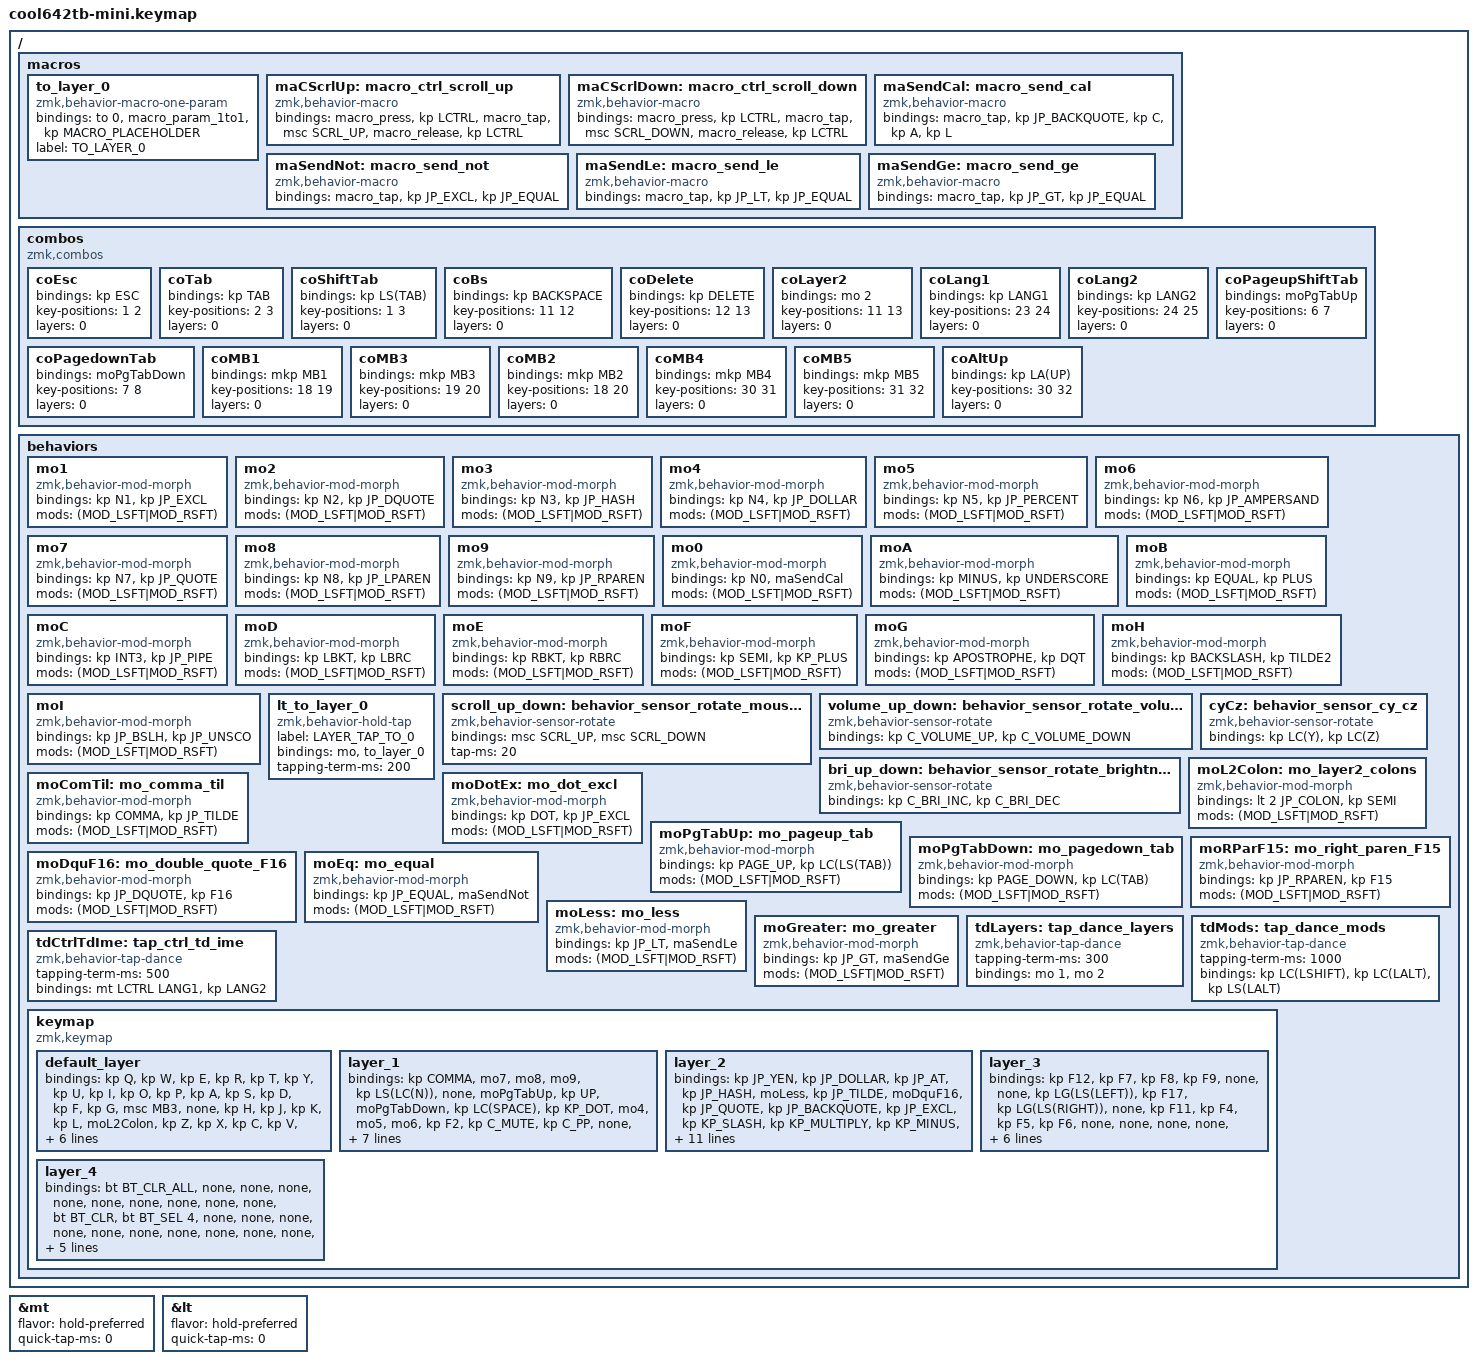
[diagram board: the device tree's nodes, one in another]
#include <behaviors.dtsi>
#include <dt-bindings/zmk/bt.h>
#include <dt-bindings/zmk/keys.h>
#include <dt-bindings/zmk/pointing.h>

#define MOUSE 4
#define SCROLL 5
#define NUM 6
#define ZMK_POINTING_DEFAULT_SCRL_VAL 80
#define JP_DQUOTE       AT                // "
#define JP_AMPERSAND    CARET             // &
#define JP_QUOTE        AMPERSAND         // '
#define JP_EQUAL        UNDER             // =
#define JP_CARET        EQUAL             // ^
#define JP_YEN          0x89              // ¥
#define JP_PLUS         COLON             // +
#define JP_TILDE        PLUS              // ~
#define JP_PIPE         LS(0x89)          // |
#define JP_AT           LEFT_BRACKET      // @
#define JP_COLON        SINGLE_QUOTE      // :
#define JP_ASTERISK     DOUBLE_QUOTES     // *
#define JP_BACKQUOTE    LEFT_BRACE        // `
#define JP_UNSCO   LS(0x87)          // _
#define JP_LBRACKET     RIGHT_BRACKET     // [
#define JP_RBRACKET     BACKSLASH         // ]
#define JP_LPAREN       ASTERISK          // (
#define JP_RPAREN       LEFT_PARENTHESIS  // )
#define JP_LBRACE       RIGHT_BRACE       // {
#define JP_RBRACE       PIPE              // }
#define JP_KANA         LANGUAGE_1        // かな
#define JP_EISU         LANGUAGE_2        // 英数
#define JP_HANZEN       GRAVE             // 半角/全角
#define JP_BSLH         INT1              // (backslash)

// new define

#define JP_EXCL  LS(N1)            // !
#define JP_QUESTION     LS(SLASH)         // ?
#define JP_HASH         LS(N3)            // #
#define JP_DOLLAR       LS(N4)            // $
#define JP_PERCENT      LS(N5)            // %
#define JP_LT           LS(COMMA)         // <
#define JP_GT           LS(DOT)           // >

&mt {
    flavor = "hold-preferred";
    quick-tap-ms = <0>;
};

&lt {
    flavor = "hold-preferred";
    quick-tap-ms = <0>;
};

/ {
    macros {
        to_layer_0: to_layer_0 {
            compatible = "zmk,behavior-macro-one-param";
            #binding-cells = <1>;
            bindings = <&to 0 &macro_param_1to1 &kp MACRO_PLACEHOLDER>;
            label = "TO_LAYER_0";
        };

        maCScrlUp: macro_ctrl_scroll_up {
            compatible = "zmk,behavior-macro";
            #binding-cells = <0>;
            bindings =
                <&macro_press>,
                <&kp LCTRL>,
                <&macro_tap>,
                <&msc SCRL_UP>,
                <&macro_release>,
                <&kp LCTRL>;
        };

        maCScrlDown: macro_ctrl_scroll_down {
            compatible = "zmk,behavior-macro";
            #binding-cells = <0>;
            bindings =
                <&macro_press>,
                <&kp LCTRL>,
                <&macro_tap>,
                <&msc SCRL_DOWN>,
                <&macro_release>,
                <&kp LCTRL>;
        };

        maSendCal: macro_send_cal {
            compatible = "zmk,behavior-macro";
            #binding-cells = <0>;
            bindings = <&macro_tap>, <&kp JP_BACKQUOTE &kp C &kp A &kp L>;
        };

        maSendNot: macro_send_not {
            compatible = "zmk,behavior-macro";
            #binding-cells = <0>;
            bindings = <&macro_tap>, <&kp JP_EXCL &kp JP_EQUAL>;
        };

        maSendLe: macro_send_le {
            compatible = "zmk,behavior-macro";
            #binding-cells = <0>;
            bindings = <&macro_tap>, <&kp JP_LT &kp JP_EQUAL>;
        };

        maSendGe: macro_send_ge {
            compatible = "zmk,behavior-macro";
            #binding-cells = <0>;
            bindings = <&macro_tap>, <&kp JP_GT &kp JP_EQUAL>;
        };
    };

    combos {
        compatible = "zmk,combos";

        // combos layer0
        //Left row1

        coEsc {
            bindings = <&kp ESC>;
            key-positions = <1 2>;
            layers = <0>;
        };

        coTab {
            bindings = <&kp TAB>;
            key-positions = <2 3>;
            layers = <0>;
        };

        coShiftTab {
            bindings = <&kp LS(TAB)>;
            key-positions = <1 3>;
            layers = <0>;
        };

        //Left row2

        coBs {
            bindings = <&kp BACKSPACE>;
            key-positions = <11 12>;
            layers = <0>;
        };

        coDelete {
            bindings = <&kp DELETE>;
            key-positions = <12 13>;
            layers = <0>;
        };

        coLayer2 {
            bindings = <&mo 2>;
            key-positions = <11 13>;
            layers = <0>;
        };

        //Left row3

        coLang1 {
            bindings = <&kp LANG1>;
            key-positions = <23 24>;
            layers = <0>;
        };

        coLang2 {
            bindings = <&kp LANG2>;
            key-positions = <24 25>;
            layers = <0>;
        };

        //Left row4
        //Right row1

        coPageupShiftTab {
            bindings = <&moPgTabUp>;
            key-positions = <6 7>;
            layers = <0>;
        };

        coPagedownTab {
            bindings = <&moPgTabDown>;
            key-positions = <7 8>;
            layers = <0>;
        };

        //Right row2

        coMB1 {
            bindings = <&mkp MB1>;
            key-positions = <18 19>;
            layers = <0>;
        };

        coMB3 {
            bindings = <&mkp MB3>;
            key-positions = <19 20>;
            layers = <0>;
        };

        coMB2 {
            bindings = <&mkp MB2>;
            key-positions = <18 20>;
            layers = <0>;
        };

        //Right row3

        coMB4 {
            bindings = <&mkp MB4>;
            key-positions = <30 31>;
            layers = <0>;
        };

        coMB5 {
            bindings = <&mkp MB5>;
            key-positions = <31 32>;
            layers = <0>;
        };

        coAltUp {
            bindings = <&kp LA(UP)>;
            key-positions = <30 32>;
            layers = <0>;
        };
    };

    behaviors {
        mo1: mo1 {
            compatible = "zmk,behavior-mod-morph";
            #binding-cells = <0>;
            bindings = <&kp N1>, <&kp JP_EXCL>;

            mods = <(MOD_LSFT|MOD_RSFT)>;
        };

        mo2: mo2 {
            compatible = "zmk,behavior-mod-morph";
            #binding-cells = <0>;
            bindings = <&kp N2>, <&kp JP_DQUOTE>;

            mods = <(MOD_LSFT|MOD_RSFT)>;
        };

        mo3: mo3 {
            compatible = "zmk,behavior-mod-morph";
            #binding-cells = <0>;
            bindings = <&kp N3>, <&kp JP_HASH>;

            mods = <(MOD_LSFT|MOD_RSFT)>;
        };

        mo4: mo4 {
            compatible = "zmk,behavior-mod-morph";
            #binding-cells = <0>;
            bindings = <&kp N4>, <&kp JP_DOLLAR>;

            mods = <(MOD_LSFT|MOD_RSFT)>;
        };

        mo5: mo5 {
            compatible = "zmk,behavior-mod-morph";
            #binding-cells = <0>;
            bindings = <&kp N5>, <&kp JP_PERCENT>;

            mods = <(MOD_LSFT|MOD_RSFT)>;
        };

        mo6: mo6 {
            compatible = "zmk,behavior-mod-morph";
            #binding-cells = <0>;
            bindings = <&kp N6>, <&kp JP_AMPERSAND>;

            mods = <(MOD_LSFT|MOD_RSFT)>;
        };

        mo7: mo7 {
            compatible = "zmk,behavior-mod-morph";
            #binding-cells = <0>;
            bindings = <&kp N7>, <&kp JP_QUOTE>;

            mods = <(MOD_LSFT|MOD_RSFT)>;
        };

        mo8: mo8 {
            compatible = "zmk,behavior-mod-morph";
            #binding-cells = <0>;
            bindings = <&kp N8>, <&kp JP_LPAREN>;

            mods = <(MOD_LSFT|MOD_RSFT)>;
        };

        mo9: mo9 {
            compatible = "zmk,behavior-mod-morph";
            #binding-cells = <0>;
            bindings = <&kp N9>, <&kp JP_RPAREN>;

            mods = <(MOD_LSFT|MOD_RSFT)>;
        };

        mo0: mo0 {
            compatible = "zmk,behavior-mod-morph";
            #binding-cells = <0>;
            bindings = <&kp N0>, <&maSendCal>;

            mods = <(MOD_LSFT|MOD_RSFT)>;
        };

        moA: moA {
            compatible = "zmk,behavior-mod-morph";
            #binding-cells = <0>;
            bindings = <&kp MINUS>, <&kp UNDERSCORE>;

            mods = <(MOD_LSFT|MOD_RSFT)>;
        };

        moB: moB {
            compatible = "zmk,behavior-mod-morph";
            #binding-cells = <0>;
            bindings = <&kp EQUAL>, <&kp PLUS>;

            mods = <(MOD_LSFT|MOD_RSFT)>;
        };

        moC: moC {
            compatible = "zmk,behavior-mod-morph";
            #binding-cells = <0>;
            bindings = <&kp INT3>, <&kp JP_PIPE>;

            mods = <(MOD_LSFT|MOD_RSFT)>;
        };

        moD: moD {
            compatible = "zmk,behavior-mod-morph";
            #binding-cells = <0>;
            bindings = <&kp LBKT>, <&kp LBRC>;

            mods = <(MOD_LSFT|MOD_RSFT)>;
        };

        moE: moE {
            compatible = "zmk,behavior-mod-morph";
            #binding-cells = <0>;
            bindings = <&kp RBKT>, <&kp RBRC>;

            mods = <(MOD_LSFT|MOD_RSFT)>;
        };

        moF: moF {
            compatible = "zmk,behavior-mod-morph";
            #binding-cells = <0>;
            bindings = <&kp SEMI>, <&kp KP_PLUS>;

            mods = <(MOD_LSFT|MOD_RSFT)>;
        };

        moG: moG {
            compatible = "zmk,behavior-mod-morph";
            #binding-cells = <0>;
            bindings = <&kp APOSTROPHE>, <&kp DQT>;

            mods = <(MOD_LSFT|MOD_RSFT)>;
        };

        moH: moH {
            compatible = "zmk,behavior-mod-morph";
            #binding-cells = <0>;
            bindings = <&kp BACKSLASH>, <&kp TILDE2>;

            mods = <(MOD_LSFT|MOD_RSFT)>;
        };

        moI: moI {
            compatible = "zmk,behavior-mod-morph";
            #binding-cells = <0>;
            bindings = <&kp JP_BSLH>, <&kp JP_UNSCO>;

            mods = <(MOD_LSFT|MOD_RSFT)>;
        };

        lt_to_layer_0: lt_to_layer_0 {
            compatible = "zmk,behavior-hold-tap";
            label = "LAYER_TAP_TO_0";
            bindings = <&mo>, <&to_layer_0>;

            #binding-cells = <2>;
            tapping-term-ms = <200>;
        };

        scroll_up_down: behavior_sensor_rotate_mouse_wheel_up_down {
            compatible = "zmk,behavior-sensor-rotate";
            #sensor-binding-cells = <0>;
            bindings = <&msc SCRL_UP>, <&msc SCRL_DOWN>;

            tap-ms = <20>;
        };

        volume_up_down: behavior_sensor_rotate_volume_up_down {
            compatible = "zmk,behavior-sensor-rotate";
            #sensor-binding-cells = <0>;
            bindings = <&kp C_VOLUME_UP>, <&kp C_VOLUME_DOWN>;
        };

        bri_up_down: behavior_sensor_rotate_brightness_up_down {
            compatible = "zmk,behavior-sensor-rotate";
            #sensor-binding-cells = <0>;
            bindings = <&kp C_BRI_INC>, <&kp C_BRI_DEC>;
        };

        cyCz: behavior_sensor_cy_cz {
            compatible = "zmk,behavior-sensor-rotate";
            #sensor-binding-cells = <0>;
            bindings = <&kp LC(Y)>, <&kp LC(Z)>;
        };

        // new behavior

        moL2Colon: mo_layer2_colons {
            compatible = "zmk,behavior-mod-morph";
            #binding-cells = <0>;
            bindings = <&lt 2 JP_COLON>, <&kp SEMI>;

            mods = <(MOD_LSFT|MOD_RSFT)>;
        };

        moComTil: mo_comma_til {
            compatible = "zmk,behavior-mod-morph";
            #binding-cells = <0>;
            bindings = <&kp COMMA>, <&kp JP_TILDE>;

            mods = <(MOD_LSFT|MOD_RSFT)>;
        };

        moDotEx: mo_dot_excl {
            compatible = "zmk,behavior-mod-morph";
            #binding-cells = <0>;
            bindings = <&kp DOT>, <&kp JP_EXCL>;

            mods = <(MOD_LSFT|MOD_RSFT)>;
        };

        moPgTabUp: mo_pageup_tab {
            compatible = "zmk,behavior-mod-morph";
            #binding-cells = <0>;
            bindings = <&kp PAGE_UP>, <&kp LC(LS(TAB))>;

            mods = <(MOD_LSFT|MOD_RSFT)>;
        };

        moPgTabDown: mo_pagedown_tab {
            compatible = "zmk,behavior-mod-morph";
            #binding-cells = <0>;
            bindings = <&kp PAGE_DOWN>, <&kp LC(TAB)>;

            mods = <(MOD_LSFT|MOD_RSFT)>;
        };

        moRParF15: mo_right_paren_F15 {
            compatible = "zmk,behavior-mod-morph";
            #binding-cells = <0>;
            bindings = <&kp JP_RPAREN>, <&kp F15>;

            mods = <(MOD_LSFT|MOD_RSFT)>;
        };

        moDquF16: mo_double_quote_F16 {
            compatible = "zmk,behavior-mod-morph";
            #binding-cells = <0>;
            bindings = <&kp JP_DQUOTE>, <&kp F16>;

            mods = <(MOD_LSFT|MOD_RSFT)>;
        };

        moEq: mo_equal {
            compatible = "zmk,behavior-mod-morph";
            #binding-cells = <0>;
            bindings = <&kp JP_EQUAL>, <&maSendNot>;

            mods = <(MOD_LSFT|MOD_RSFT)>;
        };

        moLess: mo_less {
            compatible = "zmk,behavior-mod-morph";
            #binding-cells = <0>;
            bindings = <&kp JP_LT>, <&maSendLe>;

            mods = <(MOD_LSFT|MOD_RSFT)>;
        };

        moGreater: mo_greater {
            compatible = "zmk,behavior-mod-morph";
            #binding-cells = <0>;
            bindings = <&kp JP_GT>, <&maSendGe>;

            mods = <(MOD_LSFT|MOD_RSFT)>;
        };

        tdLayers: tap_dance_layers {
            compatible = "zmk,behavior-tap-dance";
            #binding-cells = <0>;
            tapping-term-ms = <300>;
            bindings = <&mo 1>, <&mo 2>;
        };

        tdMods: tap_dance_mods {
            compatible = "zmk,behavior-tap-dance";
            #binding-cells = <0>;
            tapping-term-ms = <1000>;
            bindings = <&kp LC(LSHIFT)>, <&kp LC(LALT)>, <&kp LS(LALT)>;
        };

        tdCtrlTdIme: tap_ctrl_td_ime {
            compatible = "zmk,behavior-tap-dance";
            #binding-cells = <0>;
            tapping-term-ms = <500>;
            bindings = <&mt LCTRL LANG1>, <&kp LANG2>;
        };

        keymap {
            compatible = "zmk,keymap";

            default_layer {
                // F13:Luncher
                // moComTil:1tap=>,(~)
                // moDotEx:1tap=>.(!)
                // tdMods:1hold=>sift+Ctrl,2hold=>Ctrl+Alt,3hold=>Shift+Alt

                bindings = <
&kp Q     &kp W      &kp E     &kp R    &kp T                                           &kp Y        &kp U  &kp I      &kp O     &kp P
&kp A     &kp S      &kp D     &kp F    &kp G          &msc MB3              &none      &kp H        &kp J  &kp K      &kp L     &moL2Colon
&kp Z     &kp X      &kp C     &kp V    &kp B          &kp F2                &none      &kp N        &kp M  &moComTil  &moDotEx  &lt 3 SLASH
&kp LALT  &lt 4 F13  &kp LGUI  &tdMods  &mt LCTRL TAB  &mt LSHIFT SPACE      &lt 3 F13  &lt 1 ENTER                              &kp JP_BSLH
                >;

                sensor-bindings = <&scroll_up_down>;
            };

            layer_1 {
                // F14:Date

                bindings = <
&kp COMMA           &mo7   &mo8                    &mo9    &kp LS(LC(N))                                    &none   &moPgTabUp  &kp UP     &moPgTabDown  &kp LC(SPACE)
&kp KP_DOT          &mo4   &mo5                    &mo6    &kp F2         &kp C_MUTE            &kp C_PP    &none   &kp LEFT    &kp DOWN   &kp RIGHT     &kp LS(SPACE)
&mo0                &mo1   &mo2                    &mo3    &kp F14        &kp C_PREVIOUS        &kp C_NEXT  &none   &kp HOME    &kp K_APP  &kp END       &none
&mt LALT LG(LS(T))  &none  &mt LGUI LG(LC(LS(T)))  &trans  &tdCtrlTdIme   &mt LSHIFT LG(V)      &kp LG(H)   &trans                                       &none
                >;

                sensor-bindings = <&volume_up_down>;
            };

            layer_2 {
                // F14:Date
                // F15:WrapBracketSwitch
                // F16:WrapQuoteSwitch

                bindings = <
&kp JP_YEN          &kp JP_DOLLAR    &kp JP_AT               &kp JP_HASH       &moLess                                                    &kp JP_TILDE       &moDquF16      &kp JP_QUOTE     &kp JP_BACKQUOTE  &kp JP_EXCL
&kp KP_SLASH        &kp KP_MULTIPLY  &kp KP_MINUS            &kp KP_PLUS       &moEq                &none                         &none   &kp JP_UNSCO       &kp JP_LPAREN  &kp JP_LBRACKET  &kp JP_LBRACE     &trans
&kp JP_PERCENT      &kp JP_CARET     &kp JP_PIPE             &kp JP_AMPERSAND  &moGreater           &none                         &none   &kp KP_MINUS       &moRParF15     &kp JP_RBRACKET  &kp JP_RBRACE     &kp JP_QUESTION
&mt LALT LG(LS(R))  &none            &mt LGUI LG(LC(LS(R)))  &trans            &mt LCTRL LG(LC(T))  &mt LSHIFT LG(LC(LA(V)))      &trans  &kp LG(LA(SPACE))                                                    &none
                >;

                sensor-bindings = <&cyCz>;
            };

            layer_3 {
                bindings = <
&kp F12  &kp F7  &kp F8    &kp F9  &none                                   &none  &kp LG(LS(LEFT))  &kp F17  &kp LG(LS(RIGHT))  &none
&kp F11  &kp F4  &kp F5    &kp F6  &none      &none                 &none  &none  &kp LG(LEFT)      &kp F18  &kp LG(RIGHT)      &none
&kp F10  &kp F1  &kp F2    &kp F3  &none      &none                 &none  &none  &kp F19           &kp F20  &kp F21            &trans
&trans   &none   &kp LGUI  &trans  &kp LCTRL  &mt LSHIFT LG(LS(V))  &none  &none
                >;

                sensor-bindings = <&bri_up_down>;
            };

            layer_4 {
                bindings = <
&bt BT_CLR_ALL  &none         &none         &none         &none                    &none  &none  &none  &none  &none
&bt BT_CLR      &bt BT_SEL 4  &none         &none         &none  &none      &none  &none  &none  &none  &none  &none
&bt BT_SEL 0    &bt BT_SEL 1  &bt BT_SEL 2  &bt BT_SEL 3  &none  &none      &none  &none  &none  &none  &none  &none
&none           &trans        &none         &none         &none  &none      &none  &none                       &none
                >;

                sensor-bindings = <&scroll_up_down>;
            };
        };
    };
};
